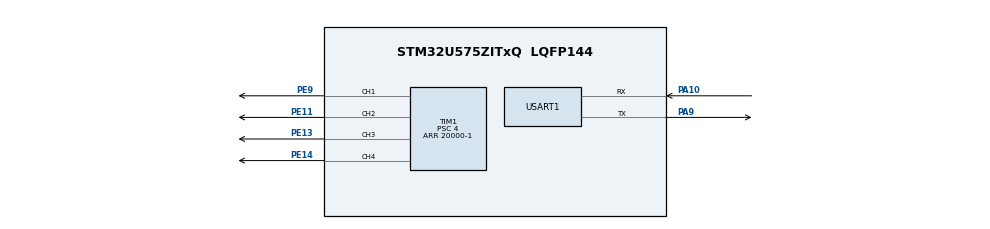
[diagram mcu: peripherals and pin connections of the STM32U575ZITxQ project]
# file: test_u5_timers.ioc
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CORTEX_M33_NS.userName=CORTEX_M33
Mcu.Family=STM32U5
Mcu.Name=STM32U575ZITxQ
Mcu.Package=LQFP144
NVIC.PriorityGroup=NVIC_PRIORITYGROUP_4
NVIC.USART1_IRQn=true\:0\:0\:false\:false\:true\:true\:true\:true
PA10.Mode=Asynchronous
PA10.Signal=USART1_RX
PA13\ (JTMS/SWDIO).Mode=Trace_Asynchronous_SW
PA13\ (JTMS/SWDIO).Signal=DEBUG_JTMS-SWDIO
PA14\ (JTCK/SWCLK).Mode=Trace_Asynchronous_SW
PA14\ (JTCK/SWCLK).Signal=DEBUG_JTCK-SWCLK
PA9.Mode=Asynchronous
PA9.Signal=USART1_TX
PB3\ (JTDO/TRACESWO).Mode=Trace_Asynchronous_SW
PB3\ (JTDO/TRACESWO).Signal=DEBUG_JTDO-SWO
PE11.Signal=S_TIM1_CH2
PE13.Signal=S_TIM1_CH3
PE14.Signal=S_TIM1_CH4
PE9.Signal=S_TIM1_CH1
PWR.PowerMode=PWR_SMPS_SUPPLY
ProjectManager.HeapSize=0x200
ProjectManager.StackSize=0x400
ProjectManager.TargetToolchain=STM32CubeIDE
RCC.ADCFreq_Value=16000000
RCC.DACCLockSelectionVirtual=RCC_DAC1CLKSOURCE_LSI
RCC.DACCLockSelectionVirtualString=RCC_DAC1CLKSOURCE_LSI
RCC.EPOD_VALUE=4000000
RCC.HSE_VALUE=16000000
RCC.HSI48_VALUE=48000000
RCC.HSI_VALUE=16000000
RCC.LSE_VALUE=32768
RCC.LSIDIV_VALUE=32000
RCC.MSI_VALUE=4000000
RCC.USBFreq_Value=48000000
RCC.VCOOutputFreq_Value=516000000
SH.S_TIM1_CH1.0=TIM1_CH1,PWM Generation1 CH1
SH.S_TIM1_CH2.0=TIM1_CH2,PWM Generation2 CH2
SH.S_TIM1_CH3.0=TIM1_CH3,PWM Generation3 CH3
SH.S_TIM1_CH4.0=TIM1_CH4,PWM Generation4 CH4
TIM1.Channel-PWM\ Generation1\ CH1=TIM_CHANNEL_1
TIM1.Channel-PWM\ Generation2\ CH2=TIM_CHANNEL_2
TIM1.Channel-PWM\ Generation3\ CH3=TIM_CHANNEL_3
TIM1.Channel-PWM\ Generation4\ CH4=TIM_CHANNEL_4
TIM1.PeriodNoDither=20000-1
TIM1.Prescaler=4
USART1.VirtualMode-Asynchronous=VM_ASYNC
VP_ICACHE_VS_ICACHE.Mode=DirectMappedCache
VP_PWR_VS_LPOM.Mode=PowerOptimisation
VP_TIM1_VS_ClockSourceINT.Mode=Internal
board=custom

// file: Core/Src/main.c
/* USER CODE BEGIN Header */
/**
  ******************************************************************************
  * @file           : main.c
  * @brief          : Main program body
  ******************************************************************************
  * @attention
  *
  * Copyright (c) 2022 STMicroelectronics.
  * All rights reserved.
  *
  * This software is licensed under terms that can be found in the LICENSE file
  * in the root directory of this software component.
  * If no LICENSE file comes with this software, it is provided AS-IS.
  *
  ******************************************************************************
  */
/* USER CODE END Header */
#include "main.h"
#include "icache.h"
#include "tim.h"
#include "usart.h"
#include "gpio.h"

/* USER CODE BEGIN Includes */
#include "servoMotor.h"
/* USER CODE END Includes */

void SystemClock_Config(void);
static void SystemPower_Config(void);

int main(void)
{

  /* MCU Configuration--------------------------------------------------------*/

  /* Reset of all peripherals, Initializes the Flash interface and the Systick. */
  HAL_Init();

  /* Configure the system clock */
  SystemClock_Config();

  /* Configure the System Power */
  SystemPower_Config();

  /* Initialize all configured peripherals */
  MX_GPIO_Init();
  MX_ICACHE_Init();
  MX_TIM1_Init();
  MX_USART1_UART_Init();
  /* USER CODE BEGIN 2 */
  /* Config Servo Motors */
  servoMotor_Init(SERVO_MODEL_DM996);
  /* Start Servo Motors PWM */
  servoMotor_Start();
  /* USER CODE END 2 */

  /* Infinite loop */
  /* USER CODE BEGIN WHILE */
  float angleDegrees = 0.0f;
  ServoMotorAngleConfig_t motorAngleConfig = {0.0f};
  while (1)
  {
    /* USER CODE END WHILE */

    /* USER CODE BEGIN 3 */

	  for(uint8_t i=0u; i<SERVO_MOTOR_NUM_MAX; i++)
	  {
		  motorAngleConfig[i] = angleDegrees;
	  }

	  servoMotor_SetAngles(motorAngleConfig);
	  HAL_Delay(1000u);

	  if(angleDegrees + 10.0f > 180.0f)
	  {
		  angleDegrees = 0.0f;
	  }
	  else
	  {
		  angleDegrees += 10.0f;
	  }
  }
  /* USER CODE END 3 */
}

void SystemClock_Config(void)
{
  RCC_OscInitTypeDef RCC_OscInitStruct = {0};
  RCC_ClkInitTypeDef RCC_ClkInitStruct = {0};

  /** Configure the main internal regulator output voltage
  */
  if (HAL_PWREx_ControlVoltageScaling(PWR_REGULATOR_VOLTAGE_SCALE4) != HAL_OK)
  {
    Error_Handler();
  }

  /** Initializes the CPU, AHB and APB buses clocks
  */
  RCC_OscInitStruct.OscillatorType = RCC_OSCILLATORTYPE_MSI;
  RCC_OscInitStruct.MSIState = RCC_MSI_ON;
  RCC_OscInitStruct.MSICalibrationValue = RCC_MSICALIBRATION_DEFAULT;
  RCC_OscInitStruct.MSIClockRange = RCC_MSIRANGE_4;
  RCC_OscInitStruct.PLL.PLLState = RCC_PLL_NONE;
  if (HAL_RCC_OscConfig(&RCC_OscInitStruct) != HAL_OK)
  {
    Error_Handler();
  }

  /** Initializes the CPU, AHB and APB buses clocks
  */
  RCC_ClkInitStruct.ClockType = RCC_CLOCKTYPE_HCLK|RCC_CLOCKTYPE_SYSCLK
                              |RCC_CLOCKTYPE_PCLK1|RCC_CLOCKTYPE_PCLK2
                              |RCC_CLOCKTYPE_PCLK3;
  RCC_ClkInitStruct.SYSCLKSource = RCC_SYSCLKSOURCE_MSI;
  RCC_ClkInitStruct.AHBCLKDivider = RCC_SYSCLK_DIV1;
  RCC_ClkInitStruct.APB1CLKDivider = RCC_HCLK_DIV1;
  RCC_ClkInitStruct.APB2CLKDivider = RCC_HCLK_DIV1;
  RCC_ClkInitStruct.APB3CLKDivider = RCC_HCLK_DIV1;

  if (HAL_RCC_ClockConfig(&RCC_ClkInitStruct, FLASH_LATENCY_0) != HAL_OK)
  {
    Error_Handler();
  }
}

/**
  * @brief Power Configuration
  * @retval None
  */
static void SystemPower_Config(void)
{

  /*
   * Switch to SMPS regulator instead of LDO
   */
  if (HAL_PWREx_ConfigSupply(PWR_SMPS_SUPPLY) != HAL_OK)
  {
    Error_Handler();
  }
}

void Error_Handler(void)
{
  __disable_irq();
  while (1)
  {
  }
}
